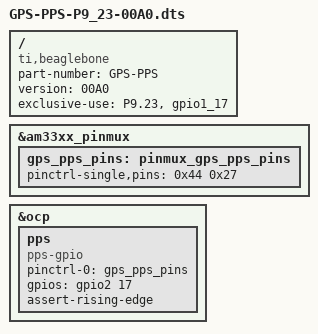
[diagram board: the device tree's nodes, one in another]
/*
 * Copyright (C) 2014 samuel.bucquet@gmail.com
 * based on the work of the8thlayerof.net
 *
 * GPS cape for a PPS TTL on P9_23 
 *
 * This program is free software; you can redistribute it and/or modify
 * it under the terms of the GNU General Public License version 2 as
 * published by the Free Software Foundation.
 */
/dts-v1/;
/plugin/;

/ {
    compatible = "ti,beaglebone", "ti,beaglebone-black";

        /* identification */
        part-number = "GPS-PPS";
        version = "00A0";

        /* state the resources this cape uses */
        exclusive-use =
                /* the pin header uses */
                "P9.23",        /* gpio1_17   */
                /* the hardware ip uses */
                "gpio1_17";

        fragment@0 {
                target = <&am33xx_pinmux>;
                __overlay__ {
                        gps_pps_pins: pinmux_gps_pps_pins {
                                pinctrl-single,pins = <
                                        0x44 0x27 /* P9.23 gpio1_17 pulldown */
                                >;
                        };
                                        
                };
        };

        fragment@1 {
                target = <&ocp>;
                
                __overlay__ {
                    pps {
                        compatible = "pps-gpio";
                        status = "okay";
                        pinctrl-names = "default";
                        pinctrl-0 = <&gps_pps_pins>;
                        gpios = <&gpio2 17 0 >;
                        assert-rising-edge;
                    };
                };
        };
};
